# G32F031 register map
File version: 1.0
CPU: CM0PLUS r0p1, little endian, no MPU, no FPU, 2 interrupt priority bits
Registers are 32-bit, read-write, reset 0x0 unless marked. A register's access mark holds for its fields unless they carry their own. Offsets are from the block's base; [hi:lo] are bit positions.

## IWDT — Independent watchdog
Base 0x40002800
0x00 KEY wo
  [15:0] KEY — Key value (write only, read 0000h)
0x04 PSC reset 0x7 — Prescaler register
  [2:0] PSC — Prescaler divider
0x08 RLR reset 0xFFF — Reload register
  [11:0] RLR — Watchdog counter reload value
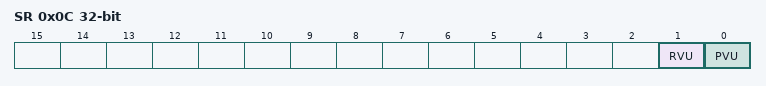
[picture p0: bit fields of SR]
0x0C SR ro — Status register
  [1] RVU — Watchdog prescaler value update
  [0] PVU — Watchdog counter reload value update

## LPTMR — Low-power timer
Base 0x40002000
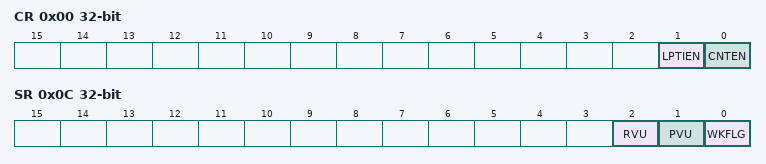
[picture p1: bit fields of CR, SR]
0x00 CR — Control register
  [1] LPTIEN — Module interrupt enable
  [0] CNTEN — Module enablement
0x04 PSC — Prescaler register
  [15:0] PSC — Prescaler divider
0x08 WKVAL reset 0xFFFF — Wakeup Value register
  [15:0] WKVAL — Awakening Value
0x0C SR ro — Status register
  [2] RVU — Reload value update indication, automatically reset by hardware after update.
  [1] PVU — PS value update indicator, hardware automatically resets after update.
  [0] WKFLG — Status Register, read SR register clear.
0x10 CNT ro — Counter register
  [15:0] CNT — Counter Value

## OPA
Base 0x40005800
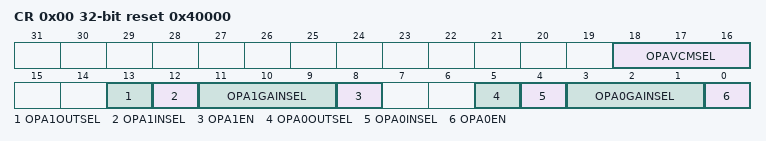
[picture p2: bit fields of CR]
0x00 CR reset 0x40000 — Control register
  [18:16] OPAVCMSEL — OPA VCM Selection
  [13] OPA1OUTSEL — OPA1 Output Selection
  [12] OPA1INSEL — OPA1 Input Selection
  [11:9] OPA1GAINSEL — OPA1 Gain Selection
  [8] OPA1EN — OPA1 Enable
  [5] OPA0OUTSEL — OPA0 Output Selection
  [4] OPA0INSEL — OPA0 Input Selection
  [3:1] OPA0GAINSEL — OPA0 Gain Selection
  [0] OPA0EN — OPA0 Enable

## PMU — Power Manage Unit
Base 0x40000000
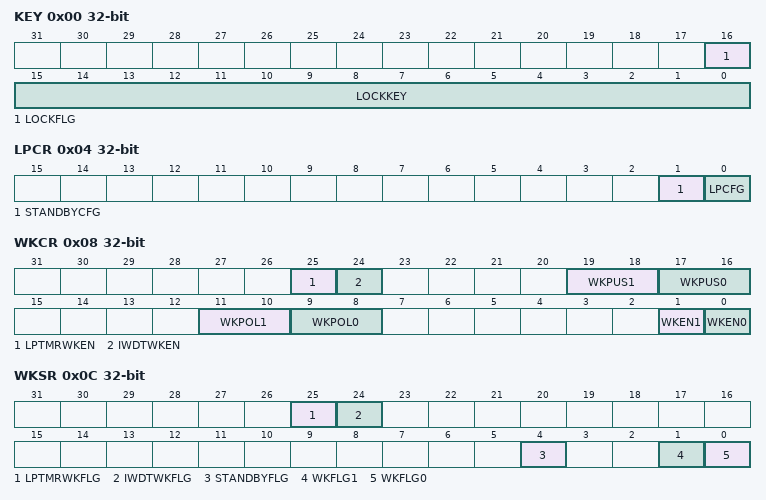
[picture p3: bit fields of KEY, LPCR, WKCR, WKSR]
0x00 KEY access per field — Read-Write Protection Register
  [16] LOCKFLG ro — PMU register lock flag
  [15:0] LOCKKEY wo — Counter enable
0x04 LPCR — Low Power Mode Register
  [1] STANDBYCFG — STANDBY Operation Mode
  [0] LPCFG — Low Power Mode
0x08 WKCR — Low-power wake-up control register
  [25] LPTMRWKEN — Enable LPTMR wake-up in STANDBY mode
  [24] IWDTWKEN — Enable IWDT wake-up in STANDBY mode
  [19:18] WKPUS1 — Wake-up pin 1 pull-up/pull-down control in STANDBY mode
  [17:16] WKPUS0 — Wake-up pin 0 pull-up/pull-down control in STANDBY mode
  [11:10] WKPOL1 — Wake-up polarity of pin 1 for STANDBY
  [9:8] WKPOL0 — Wake-up polarity of pin 0 for STANDBY
  [1] WKEN1 — Enable wake-up from STANDBY by pin 1
  [0] WKEN0 — Enable wake-up from STANDBY by pin 0
0x0C WKSR — Low Power Wake-up Status Register
  [25] LPTMRWKFLG — LPTMR to STANDBY wake-up flag
  [24] IWDTWKFLG — IWDT Standby Wake-up Flag
  [4] STANDBYFLG — STANDBY Event Flag
  [1] WKFLG1 — Wake-up pin 1 to STANDBY wake-up flag
  [0] WKFLG0 — Wake-up pin 0 to STANDBY wake-up flag
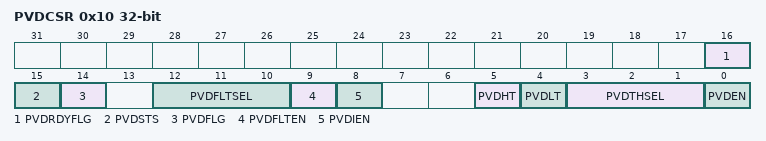
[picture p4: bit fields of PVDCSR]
0x10 PVDCSR — PVD Control/Status Register
  [16] PVDRDYFLG — PVD Ready
  [15] PVDSTS — PVD Monitoring Results Output
  [14] PVDFLG — PVD Monitoring Event Flag
  [12:10] PVDFLTSEL — PVD filter length select
  [9] PVDFLTEN — PVD filter enable
  [8] PVDIEN — PVD monitoring event interrupt enable
  [5] PVDHT — PVD above threshold voltage event monitoring.
  [4] PVDLT — PVD below threshold voltage event detection.
  [3:1] PVDTHSEL — PVD threshold voltage configuration
  [0] PVDEN — PVD Enable

## RCC — Reset and clock control
Base 0x40020400
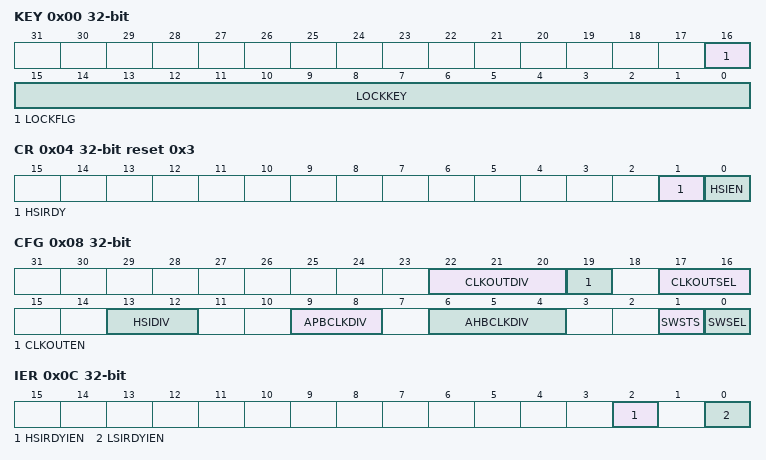
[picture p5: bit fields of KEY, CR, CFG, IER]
0x00 KEY access per field — RCC KEY register
  [16] LOCKFLG ro — Register Write Protection Flag
  [15:0] LOCKKEY wo — Password protection configuration for write operations
0x04 CR access per field reset 0x3 — RCC control register
  [1] HSIRDY ro — HSI clock stabilization flag
  [0] HSIEN rw — HSI clock enable
0x08 CFG access per field — RCC configuration register
  [22:20] CLKOUTDIV rw — Clock output division
  [19] CLKOUTEN rw — Clock output enable
  [17:16] CLKOUTSEL rw — Clock output select
  [13:12] HSIDIV rw — System clock HSI branch division
  [9:8] APBCLKDIV rw — APB clock division
  [6:4] AHBCLKDIV rw — AHB clock division
  [1] SWSTS ro — System clock select flag
  [0] SWSEL rw — System clock select
0x0C IER — RCC Interrupt Enable Register
  [2] HSIRDYIEN — HSI clock stabilization interrupt enable
  [0] LSIRDYIEN — LSI clock stabilization interrupt enable
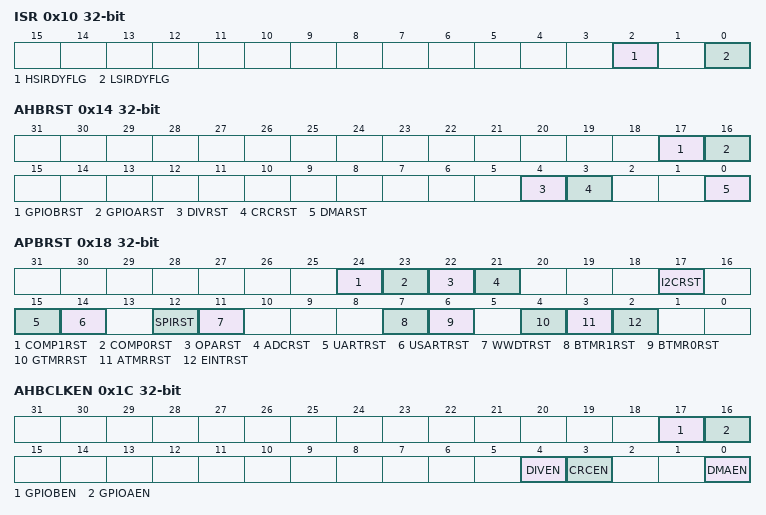
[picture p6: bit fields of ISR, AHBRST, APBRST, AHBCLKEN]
0x10 ISR — RCC Interrupt Flag Status Register
  [2] HSIRDYFLG — HSI clock stabilization interrupt flag
  [0] LSIRDYFLG — LSI clock stabilization interrupt flag
0x14 AHBRST — RCC AHB Clock Reset Register
  [17] GPIOBRST — GPIOB reset
  [16] GPIOARST — GPIOA reset
  [4] DIVRST — DIV shift reset
  [3] CRCRST — CRC reset
  [0] DMARST — DMA reset
0x18 APBRST — RCC APB Clock Reset Register
  [24] COMP1RST — COMP1 reset
  [23] COMP0RST — COMP0 reset
  [22] OPARST — OPA reset
  [21] ADCRST — ADC reset
  [17] I2CRST — I2C reset
  [15] UARTRST — UART reset
  [14] USARTRST — USART reset
  [12] SPIRST — SPI reset
  [11] WWDTRST — WWDT reset
  [7] BTMR1RST — BTMR1 reset
  [6] BTMR0RST — BTMR0 reset
  [4] GTMRRST — GTMR reset
  [3] ATMRRST — ATMR reset
  [2] EINTRST — EINT reset
0x1C AHBCLKEN — RCC AHB Clock Enable Register
  [17] GPIOBEN — GPIOB clock enable
  [16] GPIOAEN — GPIOA clock enable
  [4] DIVEN — DIV SHIFT clock enable
  [3] CRCEN — CRC clock enable
  [0] DMAEN — DMA clock enable
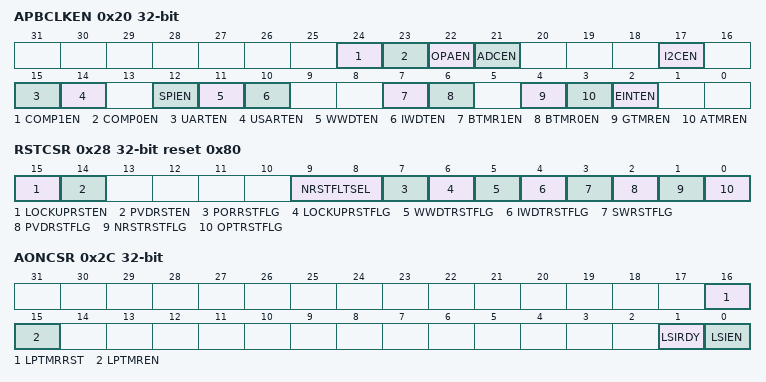
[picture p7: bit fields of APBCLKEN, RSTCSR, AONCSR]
0x20 APBCLKEN — RCC APB Clock Enable Register
  [24] COMP1EN — COMP1 enable
  [23] COMP0EN — COMP0 enable
  [22] OPAEN — OPA enable
  [21] ADCEN — ADC enable
  [17] I2CEN — I2C enable
  [15] UARTEN — UART enable
  [14] USARTEN — USART enable
  [12] SPIEN — SPI enable
  [11] WWDTEN — WWDT enable
  [10] IWDTEN — IWDT enable
  [7] BTMR1EN — BTMR1 enable
  [6] BTMR0EN — BTMR0 enable
  [4] GTMREN — GTMR enable
  [3] ATMREN — ATMR enable
  [2] EINTEN — EINT enable
0x24 ADCCR — RCC ADC Clock Control Register
  [1:0] ADCCLKDIV — ADC clock division
0x28 RSTCSR reset 0x80 — RCC Reset Control and Status Register
  [15] LOCKUPRSTEN — LOCKUP system reset enable
  [14] PVDRSTEN — PVD system reset enable
  [9:8] NRSTFLTSEL — NRST filter select
  [7] PORRSTFLG — POR/PDR reset flag
  [6] LOCKUPRSTFLG — LOCKUP system reset flag
  [5] WWDTRSTFLG — WWDT system reset flag
  [4] IWDTRSTFLG — IWDT system reset flag
  [3] SWRSTFLG — Soft system reset flag
  [2] PVDRSTFLG — PVD system reset flag
  [1] NRSTRSTFLG — NRST reset flag
  [0] OPTRSTFLG — OB reload system reset flag
0x2C AONCSR access per field — AON Control Register
  [16] LPTMRRST rw — LPTMR reset
  [15] LPTMREN rw — LPTMR clock enable
  [1] LSIRDY ro — LSI clock ready flag
  [0] LSIEN rw — LSI clock enable
